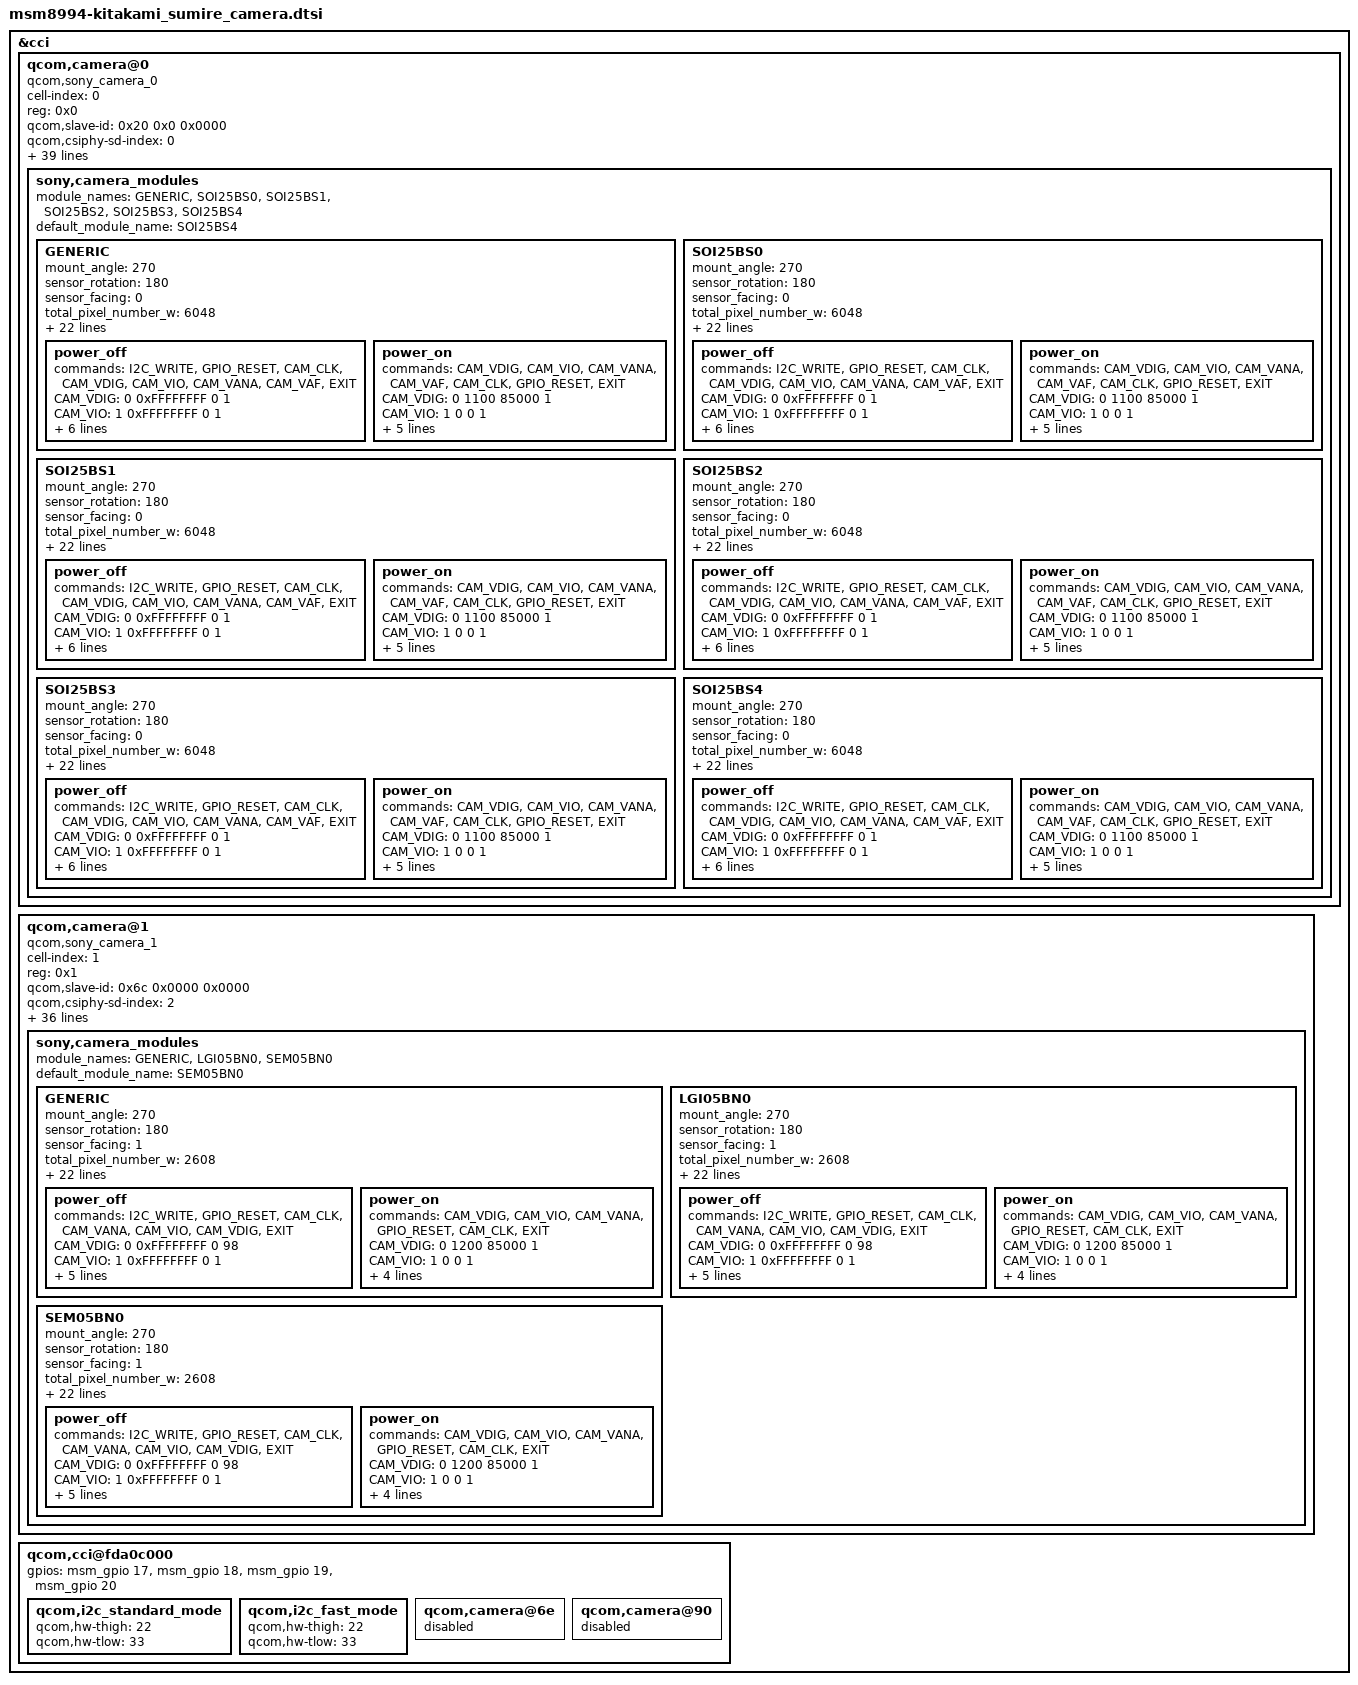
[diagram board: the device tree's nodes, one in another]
&cci {
	qcom,camera@0 {
		cell-index = <0>;
		compatible = "qcom,sony_camera_0";
		reg = <0x0>;
		status = "ok";
		qcom,slave-id = <0x20 0x0 0x0000>;
		qcom,csiphy-sd-index = <0>;
		qcom,csid-sd-index = <0>;
		qcom,mount-angle = <0>;
		qcom,sensor-name = "sony_camera_0";
		cam_vdig-supply = <&pm8994_l3>;
		cam_vana-supply = <&pm8994_l17>;
		cam_vio-supply = <&pm8994_lvs1>;
		cam_vaf-supply = <&pm8994_l23>;
		qcom,cam-vreg-name = "cam_vdig", "cam_vana", "cam_vio",
				     "cam_vaf";
		qcom,cam-vreg-type = <0 0 1 0>;
		qcom,cam-vreg-min-voltage = <1100000 2200000 0 2800000>;
		qcom,cam-vreg-max-voltage = <1100000 2200000 0 2800000>;
		qcom,cam-vreg-op-mode = <105000 85600 0 300000>;
		qcom,gpio-no-mux = <0>;
		pinctrl-names = "cam_default", "cam_suspend";
		pinctrl-0 = <&cam_sensor_mclk0_active &cam_sensor_rear_active>;
		pinctrl-1 = <&cam_sensor_mclk0_suspend &cam_sensor_rear_suspend>;
		gpios = <&msm_gpio 13 0>,
			<&msm_gpio 88 0>;
		qcom,gpio-reset = <1>;
		qcom,gpio-req-tbl-num = <0 1>;
		qcom,gpio-req-tbl-flags = <1 0>;
		qcom,gpio-req-tbl-label = "CAMIF_MCLK0",
					  "CAM_RESET0";
		qcom,csi-lane-assign = <0x4320>;
		qcom,csi-lane-mask = <0x1F>;
		qcom,sensor-position = <0>;
		qcom,sensor-mode = <1>;
		qcom,cci-master = <0>;
		clocks = <&clock_mmss clk_mclk0_clk_src>,
				<&clock_mmss clk_camss_mclk0_clk>;
		clock-names = "cam_src_clk", "cam_clk";
		sony,i2c_addr = <0x20>;
		sony,eeprom_addr = <0xA0>;
		sony,eeprom_type = <0>;
		sony,eeprom_max_len = <2048>;
		sony,gpio_af = <0>;
		sony,subdev_code = <0x3007>;
		sony,camera_modules {
			module_names = "GENERIC", "SOI25BS0",
					"SOI25BS1", "SOI25BS2", "SOI25BS3", "SOI25BS4";
			default_module_name = "SOI25BS4";
			GENERIC {
				mount_angle = <270>;
				sensor_rotation = <180>;
				sensor_facing = <0>;
				total_pixel_number_w = <6048>;
				total_pixel_number_h = <4264>;
				active_pixel_number_x = <56>;
				active_pixel_number_y = <88>;
				active_pixel_number_w = <5984>;
				active_pixel_number_h = <4160>;
				min_focus_distance = <120>;
				hyper_focal_distance = <3720>;
				diagonal_len = "8.17";
				unit_cell_size_w = "1.12";
				unit_cell_size_h = "1.12";
				min_f_number = "2.00";
				max_f_number = "2.00";
				has_focus_actuator = <1>;
				has_3a = <0>;
				i2c_freq_mode = <3>;
				has_pdaf = <1>;
				pdaf_free_area_num = <8>;
				pdaf_fixed_area_size_w = <16>;
				pdaf_fixed_area_size_h = <12>;
				pll_num = <18>;
				pll = <182 109 112 112 122 109 182 75 112 112 182 182 182 182 142 175 104 182>;
				power_off {
					commands =
						"I2C_WRITE",
						"GPIO_RESET",
						"CAM_CLK",
						"CAM_VDIG",
						"CAM_VIO",
						"CAM_VANA",
						"CAM_VAF",
						"EXIT";
					CAM_VDIG =
						<0 0xFFFFFFFF 0 1>;
					CAM_VIO = <1 0xFFFFFFFF 0 1>;
					CAM_VANA =
						<2 0xFFFFFFFF 0 1>;
					CAM_VAF = <3 0xFFFFFFFF 0 99>;
					GPIO_RESET = <5 0x0 0 1>;
					CAM_CLK = <6 0xFFFFFFFF 0 15>;
					I2C_WRITE = <7 0x0100 0 100>;
					EXIT = <8 0x0 0 0>;
				};
				power_on {
					commands =
						"CAM_VDIG",
						"CAM_VIO",
						"CAM_VANA",
						"CAM_VAF",
						"CAM_CLK",
						"GPIO_RESET",
						"EXIT";
					CAM_VDIG = <0 1100 85000 1>;
					CAM_VIO = <1 0 0 1>;
					CAM_VANA = <2 2200 103000 1>;
					CAM_VAF = <3 2800 106500 1>;
					CAM_CLK = <6 0 0 10>;
					GPIO_RESET = <5 1 0 25>;
					EXIT = <8 0x0 0 0>;
				};
			};
			SOI25BS0 {
				mount_angle = <270>;
				sensor_rotation = <180>;
				sensor_facing = <0>;
				total_pixel_number_w = <6048>;
				total_pixel_number_h = <4264>;
				active_pixel_number_x = <56>;
				active_pixel_number_y = <88>;
				active_pixel_number_w = <5984>;
				active_pixel_number_h = <4160>;
				min_focus_distance = <120>;
				hyper_focal_distance = <3720>;
				diagonal_len = "8.17";
				unit_cell_size_w = "1.12";
				unit_cell_size_h = "1.12";
				min_f_number = "2.00";
				max_f_number = "2.00";
				has_focus_actuator = <1>;
				has_3a = <0>;
				i2c_freq_mode = <3>;
				has_pdaf = <1>;
				pdaf_free_area_num = <8>;
				pdaf_fixed_area_size_w = <16>;
				pdaf_fixed_area_size_h = <12>;
				pll_num = <18>;
				pll = <182 109 112 112 122 109 182 75 112 112 182 182 182 182 142 175 104 182>;
				power_off {
					commands =
						"I2C_WRITE",
						"GPIO_RESET",
						"CAM_CLK",
						"CAM_VDIG",
						"CAM_VIO",
						"CAM_VANA",
						"CAM_VAF",
						"EXIT";
					CAM_VDIG =
						<0 0xFFFFFFFF 0 1>;
					CAM_VIO = <1 0xFFFFFFFF 0 1>;
					CAM_VANA =
						<2 0xFFFFFFFF 0 1>;
					CAM_VAF = <3 0xFFFFFFFF 0 99>;
					GPIO_RESET = <5 0x0 0 1>;
					CAM_CLK = <6 0xFFFFFFFF 0 15>;
					I2C_WRITE = <7 0x0100 0 100>;
					EXIT = <8 0x0 0 0>;
				};
				power_on {
					commands =
						"CAM_VDIG",
						"CAM_VIO",
						"CAM_VANA",
						"CAM_VAF",
						"CAM_CLK",
						"GPIO_RESET",
						"EXIT";
					CAM_VDIG = <0 1100 85000 1>;
					CAM_VIO = <1 0 0 1>;
					CAM_VANA = <2 2200 103000 1>;
					CAM_VAF = <3 2800 106500 1>;
					CAM_CLK = <6 0 0 10>;
					GPIO_RESET = <5 1 0 25>;
					EXIT = <8 0x0 0 0>;
				};
			};
			SOI25BS1 {
				mount_angle = <270>;
				sensor_rotation = <180>;
				sensor_facing = <0>;
				total_pixel_number_w = <6048>;
				total_pixel_number_h = <4264>;
				active_pixel_number_x = <56>;
				active_pixel_number_y = <88>;
				active_pixel_number_w = <5984>;
				active_pixel_number_h = <4160>;
				min_focus_distance = <120>;
				hyper_focal_distance = <3720>;
				diagonal_len = "8.17";
				unit_cell_size_w = "1.12";
				unit_cell_size_h = "1.12";
				min_f_number = "2.00";
				max_f_number = "2.00";
				has_focus_actuator = <1>;
				has_3a = <0>;
				i2c_freq_mode = <3>;
				has_pdaf = <1>;
				pdaf_free_area_num = <8>;
				pdaf_fixed_area_size_w = <16>;
				pdaf_fixed_area_size_h = <12>;
				pll_num = <18>;
				pll = <182 109 112 112 122 109 182 75 112 112 182 182 182 182 142 175 104 182>;
				power_off {
					commands =
						"I2C_WRITE",
						"GPIO_RESET",
						"CAM_CLK",
						"CAM_VDIG",
						"CAM_VIO",
						"CAM_VANA",
						"CAM_VAF",
						"EXIT";
					CAM_VDIG =
						<0 0xFFFFFFFF 0 1>;
					CAM_VIO = <1 0xFFFFFFFF 0 1>;
					CAM_VANA =
						<2 0xFFFFFFFF 0 1>;
					CAM_VAF = <3 0xFFFFFFFF 0 99>;
					GPIO_RESET = <5 0x0 0 1>;
					CAM_CLK = <6 0xFFFFFFFF 0 15>;
					I2C_WRITE = <7 0x0100 0 100>;
					EXIT = <8 0x0 0 0>;
				};
				power_on {
					commands =
						"CAM_VDIG",
						"CAM_VIO",
						"CAM_VANA",
						"CAM_VAF",
						"CAM_CLK",
						"GPIO_RESET",
						"EXIT";
					CAM_VDIG = <0 1100 85000 1>;
					CAM_VIO = <1 0 0 1>;
					CAM_VANA = <2 2200 103000 1>;
					CAM_VAF = <3 2800 106500 1>;
					CAM_CLK = <6 0 0 10>;
					GPIO_RESET = <5 1 0 25>;
					EXIT = <8 0x0 0 0>;
				};
			};
			SOI25BS2 {
				mount_angle = <270>;
				sensor_rotation = <180>;
				sensor_facing = <0>;
				total_pixel_number_w = <6048>;
				total_pixel_number_h = <4264>;
				active_pixel_number_x = <56>;
				active_pixel_number_y = <88>;
				active_pixel_number_w = <5984>;
				active_pixel_number_h = <4160>;
				min_focus_distance = <120>;
				hyper_focal_distance = <3720>;
				diagonal_len = "8.17";
				unit_cell_size_w = "1.12";
				unit_cell_size_h = "1.12";
				min_f_number = "2.00";
				max_f_number = "2.00";
				has_focus_actuator = <1>;
				has_3a = <0>;
				i2c_freq_mode = <3>;
				has_pdaf = <1>;
				pdaf_free_area_num = <8>;
				pdaf_fixed_area_size_w = <16>;
				pdaf_fixed_area_size_h = <12>;
				pll_num = <18>;
				pll = <182 109 112 112 122 109 182 75 112 112 182 182 182 182 142 175 104 182>;
				power_off {
					commands =
						"I2C_WRITE",
						"GPIO_RESET",
						"CAM_CLK",
						"CAM_VDIG",
						"CAM_VIO",
						"CAM_VANA",
						"CAM_VAF",
						"EXIT";
					CAM_VDIG =
						<0 0xFFFFFFFF 0 1>;
					CAM_VIO = <1 0xFFFFFFFF 0 1>;
					CAM_VANA =
						<2 0xFFFFFFFF 0 1>;
					CAM_VAF = <3 0xFFFFFFFF 0 99>;
					GPIO_RESET = <5 0x0 0 1>;
					CAM_CLK = <6 0xFFFFFFFF 0 15>;
					I2C_WRITE = <7 0x0100 0 100>;
					EXIT = <8 0x0 0 0>;
				};
				power_on {
					commands =
						"CAM_VDIG",
						"CAM_VIO",
						"CAM_VANA",
						"CAM_VAF",
						"CAM_CLK",
						"GPIO_RESET",
						"EXIT";
					CAM_VDIG = <0 1100 85000 1>;
					CAM_VIO = <1 0 0 1>;
					CAM_VANA = <2 2200 103000 1>;
					CAM_VAF = <3 2800 106500 1>;
					CAM_CLK = <6 0 0 10>;
					GPIO_RESET = <5 1 0 25>;
					EXIT = <8 0x0 0 0>;
				};
			};
			SOI25BS3 {
				mount_angle = <270>;
				sensor_rotation = <180>;
				sensor_facing = <0>;
				total_pixel_number_w = <6048>;
				total_pixel_number_h = <4264>;
				active_pixel_number_x = <56>;
				active_pixel_number_y = <88>;
				active_pixel_number_w = <5984>;
				active_pixel_number_h = <4160>;
				min_focus_distance = <120>;
				hyper_focal_distance = <3720>;
				diagonal_len = "8.17";
				unit_cell_size_w = "1.12";
				unit_cell_size_h = "1.12";
				min_f_number = "2.00";
				max_f_number = "2.00";
				has_focus_actuator = <1>;
				has_3a = <0>;
				i2c_freq_mode = <3>;
				has_pdaf = <1>;
				pdaf_free_area_num = <8>;
				pdaf_fixed_area_size_w = <16>;
				pdaf_fixed_area_size_h = <12>;
				pll_num = <18>;
				pll = <182 109 112 112 122 109 182 75 112 112 182 182 182 182 142 175 104 182>;
				power_off {
					commands =
						"I2C_WRITE",
						"GPIO_RESET",
						"CAM_CLK",
						"CAM_VDIG",
						"CAM_VIO",
						"CAM_VANA",
						"CAM_VAF",
						"EXIT";
					CAM_VDIG =
						<0 0xFFFFFFFF 0 1>;
					CAM_VIO = <1 0xFFFFFFFF 0 1>;
					CAM_VANA =
						<2 0xFFFFFFFF 0 1>;
					CAM_VAF = <3 0xFFFFFFFF 0 99>;
					GPIO_RESET = <5 0x0 0 1>;
					CAM_CLK = <6 0xFFFFFFFF 0 15>;
					I2C_WRITE = <7 0x0100 0 100>;
					EXIT = <8 0x0 0 0>;
				};
				power_on {
					commands =
						"CAM_VDIG",
						"CAM_VIO",
						"CAM_VANA",
						"CAM_VAF",
						"CAM_CLK",
						"GPIO_RESET",
						"EXIT";
					CAM_VDIG = <0 1100 85000 1>;
					CAM_VIO = <1 0 0 1>;
					CAM_VANA = <2 2200 103000 1>;
					CAM_VAF = <3 2800 106500 1>;
					CAM_CLK = <6 0 0 10>;
					GPIO_RESET = <5 1 0 25>;
					EXIT = <8 0x0 0 0>;
				};
			};
			SOI25BS4 {
				mount_angle = <270>;
				sensor_rotation = <180>;
				sensor_facing = <0>;
				total_pixel_number_w = <6048>;
				total_pixel_number_h = <4264>;
				active_pixel_number_x = <56>;
				active_pixel_number_y = <88>;
				active_pixel_number_w = <5984>;
				active_pixel_number_h = <4160>;
				min_focus_distance = <120>;
				hyper_focal_distance = <3720>;
				diagonal_len = "8.17";
				unit_cell_size_w = "1.12";
				unit_cell_size_h = "1.12";
				min_f_number = "2.00";
				max_f_number = "2.00";
				has_focus_actuator = <1>;
				has_3a = <0>;
				i2c_freq_mode = <3>;
				has_pdaf = <1>;
				pdaf_free_area_num = <8>;
				pdaf_fixed_area_size_w = <16>;
				pdaf_fixed_area_size_h = <12>;
				pll_num = <18>;
				pll = <182 109 112 112 122 109 182 75 112 112 182 182 182 182 142 175 104 182>;
				power_off {
					commands =
						"I2C_WRITE",
						"GPIO_RESET",
						"CAM_CLK",
						"CAM_VDIG",
						"CAM_VIO",
						"CAM_VANA",
						"CAM_VAF",
						"EXIT";
					CAM_VDIG =
						<0 0xFFFFFFFF 0 1>;
					CAM_VIO = <1 0xFFFFFFFF 0 1>;
					CAM_VANA =
						<2 0xFFFFFFFF 0 1>;
					CAM_VAF = <3 0xFFFFFFFF 0 99>;
					GPIO_RESET = <5 0x0 0 1>;
					CAM_CLK = <6 0xFFFFFFFF 0 15>;
					I2C_WRITE = <7 0x0100 0 100>;
					EXIT = <8 0x0 0 0>;
				};
				power_on {
					commands =
						"CAM_VDIG",
						"CAM_VIO",
						"CAM_VANA",
						"CAM_VAF",
						"CAM_CLK",
						"GPIO_RESET",
						"EXIT";
					CAM_VDIG = <0 1100 85000 1>;
					CAM_VIO = <1 0 0 1>;
					CAM_VANA = <2 2200 103000 1>;
					CAM_VAF = <3 2800 106500 1>;
					CAM_CLK = <6 0 0 10>;
					GPIO_RESET = <5 1 0 25>;
					EXIT = <8 0x0 0 0>;
				};
			};
		};
	};
	qcom,camera@1 {
		cell-index = <1>;
		compatible = "qcom,sony_camera_1";
		reg = <0x1>;
		status = "ok";
		qcom,slave-id = <0x6c 0x0000 0x0000>;
		qcom,csiphy-sd-index = <2>;
		qcom,csid-sd-index = <2>;
		qcom,mount-angle = <0>;
		qcom,sensor-name = "sony_camera_1";
		cam_vdig-supply = <&pm8994_l27>;
		cam_vana-supply = <&pm8994_l29>;
		cam_vio-supply = <&pm8994_lvs1>;
		qcom,cam-vreg-name = "cam_vdig", "cam_vana", "cam_vio";
		qcom,cam-vreg-type = <0 0 1>;
		qcom,cam-vreg-min-voltage = <1200000 2700000 0>;
		qcom,cam-vreg-max-voltage = <1200000 2700000 0>;
		qcom,cam-vreg-op-mode = <105000 85600 0>;
		qcom,gpio-no-mux = <0>;
		pinctrl-names = "cam_default", "cam_suspend";
		pinctrl-0 = <&cam_sensor_mclk2_active &cam_sensor_front_active>;
		pinctrl-1 = <&cam_sensor_mclk2_suspend &cam_sensor_front_suspend>;
		gpios = <&msm_gpio 15 0>,
			<&msm_gpio 104 0>;
		qcom,gpio-reset = <1>;
		qcom,gpio-req-tbl-num = <0 1>;
		qcom,gpio-req-tbl-flags = <1 0>;
		qcom,gpio-req-tbl-label = "CAMIF_MCLK2",
					  "CAM_RESET1";
		qcom,csi-lane-assign = <0x4320>;
		qcom,csi-lane-mask = <0x7>;
		qcom,sensor-position = <1>;
		qcom,sensor-mode = <1>;
		qcom,cci-master = <1>;
		clocks = <&clock_mmss clk_mclk2_clk_src>,
			<&clock_mmss clk_camss_mclk2_clk>;
		clock-names = "cam_src_clk", "cam_clk";
		sony,i2c_addr = <0x6c>;
		sony,eeprom_addr = <0xA0>;
		sony,eeprom_type = <0>;
		sony,eeprom_max_len = <1024>;
		sony,gpio_af = <0>;
		sony,subdev_code = <0x3007>;
		sony,camera_modules {
			module_names = "GENERIC", "LGI05BN0",
					"SEM05BN0";
			default_module_name = "SEM05BN0";
			GENERIC {
				mount_angle = <270>;
				sensor_rotation = <180>;
				sensor_facing = <1>;
				total_pixel_number_w = <2608>;
				total_pixel_number_h = <2000>;
				active_pixel_number_x = <8>;
				active_pixel_number_y = <8>;
				active_pixel_number_w = <2592>;
				active_pixel_number_h = <1944>;
				min_focus_distance = <0>;
				hyper_focal_distance = <0>;
				diagonal_len = "3.63";
				unit_cell_size_w = "1.12";
				unit_cell_size_h = "1.12";
				min_f_number = "2.40";
				max_f_number = "2.40";
				has_focus_actuator = <0>;
				has_3a = <0>;
				i2c_freq_mode = <0>;
				has_pdaf = <0>;
				pdaf_free_area_num = <0>;
				pdaf_fixed_area_size_w = <0>;
				pdaf_fixed_area_size_h = <0>;
				pll_num = <18>;
				pll = <118 118 95 118 125 118 118 125 118 118 118 118 118 118 118 118 118 118>;
				power_off {
					commands =
						"I2C_WRITE",
						"GPIO_RESET",
						"CAM_CLK",
						"CAM_VANA",
						"CAM_VIO",
						"CAM_VDIG",
						"EXIT";
					CAM_VDIG =
						<0 0xFFFFFFFF 0 98>;
					CAM_VIO = <1 0xFFFFFFFF 0 1>;
					CAM_VANA =
						<2 0xFFFFFFFF 0 1>;
					GPIO_RESET = <5 0x0 0 1>;
					CAM_CLK = <6 0xFFFFFFFF 0 1>;
					I2C_WRITE = <7 0x0100 0 100>;
					EXIT = <8 0x0 0 0>;
				};
				power_on {
					commands =
						"CAM_VDIG",
						"CAM_VIO",
						"CAM_VANA",
						"GPIO_RESET",
						"CAM_CLK",
						"EXIT";
					CAM_VDIG = <0 1200 85000 1>;
					CAM_VIO = <1 0 0 1>;
					CAM_VANA = <2 2700 103000 1>;
					GPIO_RESET = <5 1 0 1>;
					CAM_CLK = <6 0 0 1>;
					EXIT = <8 0x0 0 0>;
				};
			};
			LGI05BN0 {
				mount_angle = <270>;
				sensor_rotation = <180>;
				sensor_facing = <1>;
				total_pixel_number_w = <2608>;
				total_pixel_number_h = <2000>;
				active_pixel_number_x = <8>;
				active_pixel_number_y = <8>;
				active_pixel_number_w = <2592>;
				active_pixel_number_h = <1944>;
				min_focus_distance = <0>;
				hyper_focal_distance = <0>;
				diagonal_len = "3.63";
				unit_cell_size_w = "1.12";
				unit_cell_size_h = "1.12";
				min_f_number = "2.40";
				max_f_number = "2.40";
				has_focus_actuator = <0>;
				has_3a = <0>;
				i2c_freq_mode = <0>;
				has_pdaf = <0>;
				pdaf_free_area_num = <0>;
				pdaf_fixed_area_size_w = <0>;
				pdaf_fixed_area_size_h = <0>;
				pll_num = <18>;
				pll = <118 118 95 118 125 118 118 125 118 118 118 118 118 118 118 118 118 118>;
				power_off {
					commands =
						"I2C_WRITE",
						"GPIO_RESET",
						"CAM_CLK",
						"CAM_VANA",
						"CAM_VIO",
						"CAM_VDIG",
						"EXIT";
					CAM_VDIG =
						<0 0xFFFFFFFF 0 98>;
					CAM_VIO = <1 0xFFFFFFFF 0 1>;
					CAM_VANA =
						<2 0xFFFFFFFF 0 1>;
					GPIO_RESET = <5 0x0 0 1>;
					CAM_CLK = <6 0xFFFFFFFF 0 1>;
					I2C_WRITE = <7 0x0100 0 100>;
					EXIT = <8 0x0 0 0>;
				};
				power_on {
					commands =
						"CAM_VDIG",
						"CAM_VIO",
						"CAM_VANA",
						"GPIO_RESET",
						"CAM_CLK",
						"EXIT";
					CAM_VDIG = <0 1200 85000 1>;
					CAM_VIO = <1 0 0 1>;
					CAM_VANA = <2 2700 103000 1>;
					GPIO_RESET = <5 1 0 1>;
					CAM_CLK = <6 0 0 1>;
					EXIT = <8 0x0 0 0>;
				};
			};
			SEM05BN0 {
				mount_angle = <270>;
				sensor_rotation = <180>;
				sensor_facing = <1>;
				total_pixel_number_w = <2608>;
				total_pixel_number_h = <2000>;
				active_pixel_number_x = <8>;
				active_pixel_number_y = <8>;
				active_pixel_number_w = <2592>;
				active_pixel_number_h = <1944>;
				min_focus_distance = <0>;
				hyper_focal_distance = <0>;
				diagonal_len = "3.63";
				unit_cell_size_w = "1.12";
				unit_cell_size_h = "1.12";
				min_f_number = "2.40";
				max_f_number = "2.40";
				has_focus_actuator = <0>;
				has_3a = <0>;
				i2c_freq_mode = <0>;
				has_pdaf = <0>;
				pdaf_free_area_num = <0>;
				pdaf_fixed_area_size_w = <0>;
				pdaf_fixed_area_size_h = <0>;
				pll_num = <18>;
				pll = <118 118 95 118 125 118 118 125 118 118 118 118 118 118 118 118 118 118>;
				power_off {
					commands =
						"I2C_WRITE",
						"GPIO_RESET",
						"CAM_CLK",
						"CAM_VANA",
						"CAM_VIO",
						"CAM_VDIG",
						"EXIT";
					CAM_VDIG =
						<0 0xFFFFFFFF 0 98>;
					CAM_VIO = <1 0xFFFFFFFF 0 1>;
					CAM_VANA =
						<2 0xFFFFFFFF 0 1>;
					GPIO_RESET = <5 0x0 0 1>;
					CAM_CLK = <6 0xFFFFFFFF 0 1>;
					I2C_WRITE = <7 0x0100 0 100>;
					EXIT = <8 0x0 0 0>;
				};
				power_on {
					commands =
						"CAM_VDIG",
						"CAM_VIO",
						"CAM_VANA",
						"GPIO_RESET",
						"CAM_CLK",
						"EXIT";
					CAM_VDIG = <0 1200 85000 1>;
					CAM_VIO = <1 0 0 1>;
					CAM_VANA = <2 2700 103000 1>;
					GPIO_RESET = <5 1 0 1>;
					CAM_CLK = <6 0 0 1>;
					EXIT = <8 0x0 0 0>;
				};
			};
		};
	};

        qcom,cci@fda0c000 {
		gpios = <&msm_gpio 17 0>,
			<&msm_gpio 18 0>,
			<&msm_gpio 19 0>,
			<&msm_gpio 20 0>;
		qcom,i2c_standard_mode {
			qcom,hw-thigh = <22>;
			qcom,hw-tlow = <33>;
		};
		qcom,i2c_fast_mode {
			qcom,hw-thigh = <22>;
			qcom,hw-tlow = <33>;
		};
		/* disable Qualcomm camera sensors */
		qcom,camera@6e {
			status = "disabled";
		};
		qcom,camera@90 {
			status = "disabled";
		};
	};
};
